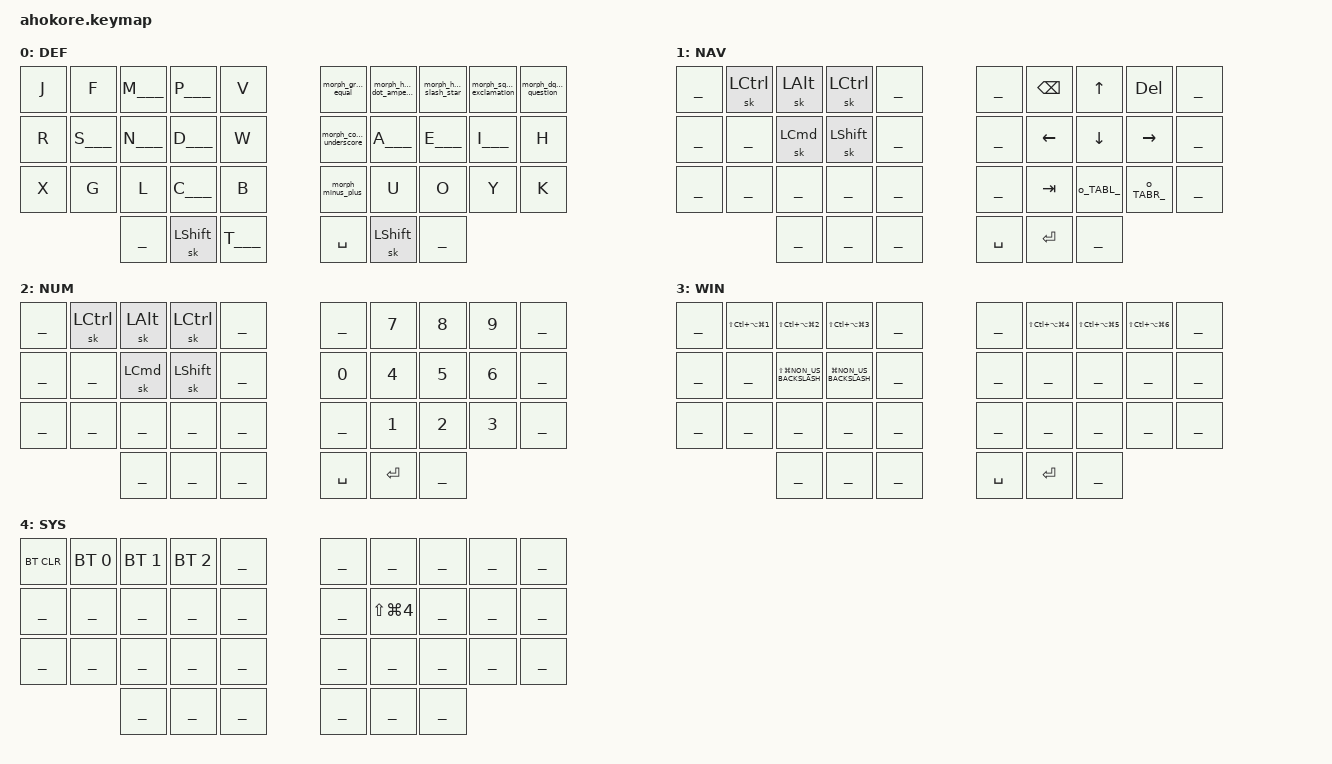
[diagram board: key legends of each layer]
#include <behaviors.dtsi>
#include <dt-bindings/zmk/keys.h>
#include <dt-bindings/zmk/bt.h>
#include "keycodes.h"

// LAYERS
#define DEF 0
#define NAV 1
#define NUM 2
#define WIN 3
#define SYS 4

&sk {
  release-after-ms = <2000>;
};

&kscan0 {
  debounce-period = <10>;
};

/ {

  behaviors {
    #include "hold_tap.dtsi"
    #include "mod_morph.dtsi"
    //#include "macros.dtsi"
  };

  combos {
    #include "combos.dtsi"
  };

  keymap {
    compatible = "zmk,keymap";

    #define _LEFT__ &kp LEFT
    #define __UP___ &kp UP
    #define _DOWN__ &kp DOWN
    #define _RIGHT_ &kp RIGHT

    #define _SPACE_ &kp SPACE
    #define __TAB__ &kp TAB
    #define _ENTER_ &kp ENTER
    #define _BKSPC_ &kp BACKSPACE
    #define __DEL__ &kp DELETE

    #define ___A___ HMRS A
    #define ___B___ &kp B
    #define ___C___ HLSYS C
    #define ___D___ HMLS D
    #define ___E___ HMRG E
    #define ___F___ &kp F
    #define ___G___ &kp G
    #define ___H___ &kp H
    #define ___I___ HLWIN I
    #define ___J___ &kp J
    #define ___K___ &kp K
    #define ___L___ &kp L
    #define ___M___ HMLO M
    #define ___N___ HMLG N
    #define ___O___ &kp O
    #define ___P___ HMLC P
    #define ___R___ &kp R
    #define ___S___ HLNUM S
    #define ___T___ HLNAV T
    #define ___U___ &kp U
    #define ___V___ &kp V
    #define ___W___ &kp W
    #define ___X___ &kp X
    #define ___Y___ &kp Y

    #define _COMMA_ &morph_comma_underscore
    #define _MINUS_ &morph_minus_plus
    #define _COLON_ &morph_colon_pipe
    #define _GRAVE_ &morph_grave_equal
    #define __DOT__ &morph_hmrc_dot_ampersand
    #define _SLASH_ &morph_hmro_slash_star
    #define _SQUOT_ &morph_squote_exclamation
    #define _DQUOT_ &morph_dquote_question

    #define _LSHFT_ &sk LEFT_SHIFT
    #define _LCTRL_ &sk LEFT_CONTROL
    #define _LOPT__ &sk LEFT_ALT
    #define _LCMD__ &sk LEFT_COMMAND

    #define _W_NEXT &kp LG(NON_US_BACKSLASH)
    #define _W_PREV &kp LS(LG(NON_US_BACKSLASH))

    #define ___0___ &kp N0
    #define ___1___ &kp N1
    #define ___2___ &kp N2
    #define ___3___ &kp N3
    #define ___4___ &kp N4
    #define ___5___ &kp N5
    #define ___6___ &kp N6
    #define ___7___ &kp N7
    #define ___8___ &kp N8
    #define ___9___ &kp N9

    #define _BRIMN_ &kp F14
    #define _BRIMX_ &kp F15

    #define _DSKT1_ &kp LS(LC(LA(LG(N1))))
    #define _DSKT2_ &kp LS(LC(LA(LG(N2))))
    #define _DSKT3_ &kp LS(LC(LA(LG(N3))))
    #define _DSKT4_ &kp LS(LC(LA(LG(N4))))
    #define _DSKT5_ &kp LS(LC(LA(LG(N5))))
    #define _DSKT6_ &kp LS(LC(LA(LG(N6))))

    #define _SCRSH_ &kp LS(LG(N4))

    #define _BTCLR_ &bt BT_CLR
    #define _BT_00_ &bt BT_SEL 0
    #define _BT_01_ &bt BT_SEL 1
    #define _BT_02_ &bt BT_SEL 2

//        _______  _______  _______  _______  _______    _______  _______  _______  _______  _______
//        _______  _______  _______  _______  _______    _______  _______  _______  _______  _______
//        _______  _______  _______  _______  _______    _______  _______  _______  _______  _______
//                          _______  _______  _______    _______  _______  _______

    base_layer {
      label = "DEF";
      bindings = <
        ___J___  ___F___  ___M___  ___P___  ___V___    _GRAVE_  __DOT__  _SLASH_  _SQUOT_  _DQUOT_
        ___R___  ___S___  ___N___  ___D___  ___W___    _COMMA_  ___A___  ___E___  ___I___  ___H___
        ___X___  ___G___  ___L___  ___C___  ___B___    _MINUS_  ___U___  ___O___  ___Y___  ___K___
                          _______  _LSHFT_  ___T___    _SPACE_  _LSHFT_  _______
      >;
    };

    nav_layer {
      label = "NAV";
      bindings = <
        _______  _LCTRL_  _LOPT__  _LCTRL_  _______    _______  _BKSPC_  __UP___  __DEL__  _______
        _______  _______  _LCMD__  _LSHFT_  _______    _______  _LEFT__  _DOWN__  _RIGHT_  _______
        _______  _______  _______  _______  _______    _______  __TAB__  o_TABL_  o_TABR_  _______
                          _______  _______  _______    _SPACE_  _ENTER_  _______
      >;
    };

    num_layer {
      label = "NUM";
      bindings = <
        _______  _LCTRL_  _LOPT__  _LCTRL_  _______    _______  ___7___  ___8___  ___9___  _______
        _______  _______  _LCMD__  _LSHFT_  _______    ___0___  ___4___  ___5___  ___6___  _______
        _______  _______  _______  _______  _______    _______  ___1___  ___2___  ___3___  _______
                          _______  _______  _______    _SPACE_  _ENTER_  _______
      >;
    };

    win_layer {
      label = "WIN";
      bindings = <
        _______  _DSKT1_  _DSKT2_  _DSKT3_  _______    _______  _DSKT4_  _DSKT5_  _DSKT6_  _______
        _______  _______  _W_PREV  _W_NEXT  _______    _______  _______  _______  _______  _______
        _______  _______  _______  _______  _______    _______  _______  _______  _______  _______
                          _______  _______  _______    _SPACE_  _ENTER_  _______
      >;
    };

    sys_layer {
      label = "SYS";
      bindings = <
        _BTCLR_  _BT_00_  _BT_01_  _BT_02_  _______    _______  _______  _______  _______  _______
        _______  _______  _______  _______  _______    _______  _SCRSH_  _______  _______  _______
        _______  _______  _______  _______  _______    _______  _______  _______  _______  _______
                          _______  _______  _______    _______  _______  _______
      >;
    };
  };
};
